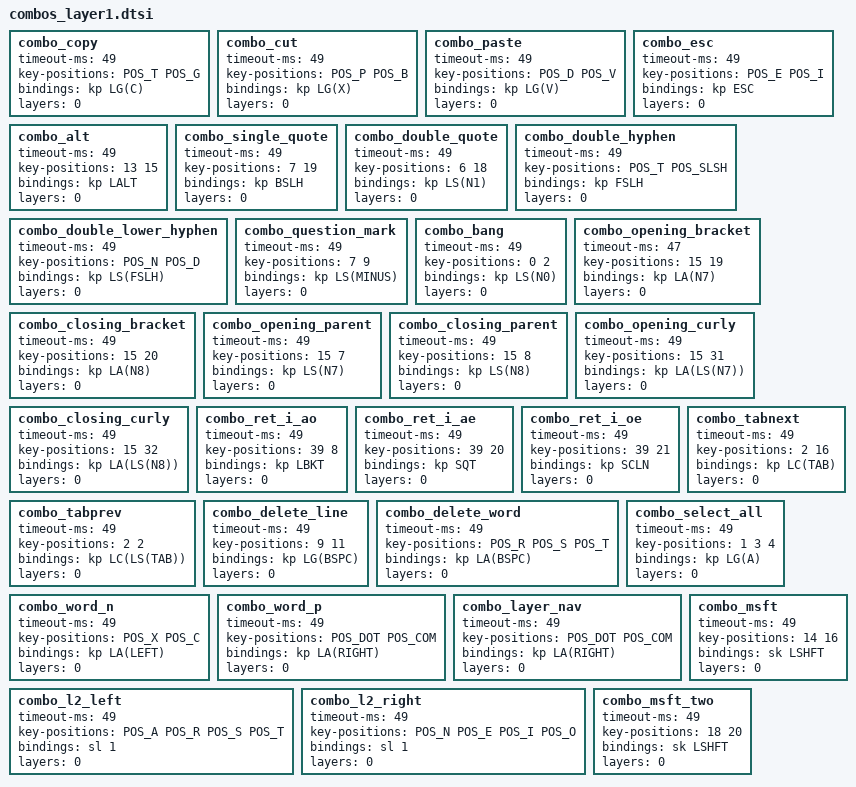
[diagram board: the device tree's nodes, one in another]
combo_copy {
    timeout-ms = <49>;
    key-positions = <POS_T POS_G>;
    bindings = <&kp LG(C)>;
    layers = <0>;
};
combo_cut {
    timeout-ms = <49>;
    key-positions = <POS_P POS_B>;
    bindings = <&kp LG(X)>;
    layers = <0>;
};
combo_paste {
    timeout-ms = <49>;
    key-positions = <POS_D POS_V>;
    bindings = <&kp LG(V)>;
    layers = <0>;
};
combo_esc {
    timeout-ms = <49>;
    key-positions = <POS_E POS_I>;
    bindings = <&kp ESC>;
    layers = <0>;
};
combo_alt {
    timeout-ms = <49>;
    key-positions = <13 15>;
    bindings = <&kp LALT>;
    layers = <0>;
};
combo_single_quote {
    timeout-ms = <49>;
    key-positions = <7 19>;
    bindings = <&kp BSLH>;  
    layers = <0>;
};
combo_double_quote {
    timeout-ms = <49>;
    key-positions = <6 18>;
    bindings = <&kp LS(N1)>;  
    layers = <0>;
};
combo_double_hyphen {
    timeout-ms = <49>;
    key-positions = <POS_T POS_SLSH>;
    bindings = <&kp FSLH>;  
    layers = <0>;
};
combo_double_lower_hyphen {
    timeout-ms = <49>;
    key-positions = <POS_N POS_D>;
    bindings = <&kp LS(FSLH)>;  
    layers = <0>;
};
combo_question_mark {
    timeout-ms = <49>;
    key-positions = <7 9>;
    bindings = <&kp LS(MINUS)>;  
    layers = <0>;
};
combo_bang {
    timeout-ms = <49>;
    key-positions = <0 2>;
    bindings = <&kp LS(N0)>;  
    layers = <0>;
};
combo_opening_bracket {
    timeout-ms = <47>;
    key-positions = <15 19>; 
    bindings = <&kp LA(N7)>; 
    layers = <0>;
};
combo_closing_bracket {
    timeout-ms = <49>;
    key-positions = <15 20>;   
    bindings = <&kp LA(N8)>; 
    layers = <0>;
};
combo_opening_parent {
    timeout-ms = <49>;
    key-positions = <15 7>;   
    bindings = <&kp LS(N7)>;
    layers = <0>;
};
combo_closing_parent {
    timeout-ms = <49>;
    key-positions = <15 8>;   
    bindings = <&kp LS(N8)>; 
    layers = <0>;
};
combo_opening_curly {
    timeout-ms = <49>;
    key-positions = <15 31>;   
    bindings = <&kp LA(LS(N7))>; 
    layers = <0>;
};
combo_closing_curly {
    timeout-ms = <49>;
    key-positions = <15 32>;   
    bindings = <&kp LA(LS(N8))>; 
    layers = <0>;
};
combo_ret_i_ao {
    timeout-ms = <49>;
    key-positions = <39 8>;
    bindings = <&kp LBKT>;   
    layers = <0>;
};
combo_ret_i_ae {
    timeout-ms = <49>;
    key-positions = <39 20>;
    bindings = <&kp SQT>;   
    layers = <0>;
};
combo_ret_i_oe {
    timeout-ms = <49>;
    key-positions = <39 21>;
    bindings = <&kp SCLN>;   
    layers = <0>;
};
combo_tabnext {
    timeout-ms = <49>;
    key-positions = <2 16>;
    bindings = <&kp LC(TAB)>;   
    layers = <0>;
};
combo_tabprev {
    timeout-ms = <49>;
    key-positions = <2 2>;
    bindings = <&kp LC(LS(TAB))>;   
    layers = <0>;
};
combo_delete_line {
    timeout-ms = <49>;
    key-positions = <9 11>;  
    bindings = <&kp LG(BSPC)>;
    layers = <0>;
};
combo_delete_word  {
    timeout-ms = <49>;
    key-positions = <POS_R POS_S POS_T>;  
    bindings = <&kp LA(BSPC)>;
    layers = <0>;
};
combo_select_all  {
    timeout-ms = <49>;
    key-positions = <1 3 4>;  
    bindings = <&kp LG(A)>;
    layers = <0>;
};
combo_word_n  {
    timeout-ms = <49>;
    key-positions = <POS_X POS_C>;  
    bindings = <&kp LA(LEFT)>;
    layers = <0>;
};
combo_word_p  {
    timeout-ms = <49>;
    key-positions = <POS_DOT POS_COM>;  
    bindings = <&kp LA(RIGHT)>;
    layers = <0>;
};
combo_layer_nav  {
    timeout-ms = <49>;
    key-positions = <POS_DOT POS_COM>;  
    bindings = <&kp LA(RIGHT)>;
    layers = <0>;
};
combo_l2_left  {
    timeout-ms = <49>;
    key-positions = <POS_A POS_R POS_S POS_T>;  
    bindings = <&sl 1>;
    layers = <0>;
};
combo_l2_right  {
    timeout-ms = <49>;
    key-positions = <POS_N POS_E POS_I POS_O>;  
    bindings = <&sl 1>;
    layers = <0>;
};
combo_msft  {
    timeout-ms = <49>;
    key-positions = <14 16>;  
    bindings = <&sk LSHFT>;
    layers = <0>;
};
combo_msft_two  {
    timeout-ms = <49>;
    key-positions = <18 20>;  
    bindings = <&sk LSHFT>;
    layers = <0>;
};







